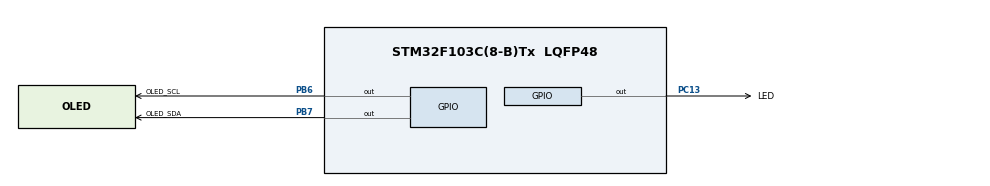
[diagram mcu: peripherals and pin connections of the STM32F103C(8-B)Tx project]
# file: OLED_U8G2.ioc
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Mcu.Family=STM32F1
Mcu.Name=STM32F103C(8-B)Tx
Mcu.Package=LQFP48
NVIC.PriorityGroup=NVIC_PRIORITYGROUP_4
PA13.Mode=Serial_Wire
PA13.Signal=SYS_JTMS-SWDIO
PA14.Mode=Serial_Wire
PA14.Signal=SYS_JTCK-SWCLK
PB6.GPIO_Label=OLED_SCL
PB6.Signal=GPIO_Output
PB7.GPIO_Label=OLED_SDA
PB7.Signal=GPIO_Output
PC13-TAMPER-RTC.GPIO_Label=LED
PC13-TAMPER-RTC.PinState=GPIO_PIN_SET
PC13-TAMPER-RTC.Signal=GPIO_Output
PD0-OSC_IN.Mode=HSE-External-Oscillator
PD0-OSC_IN.Signal=RCC_OSC_IN
PD1-OSC_OUT.Mode=HSE-External-Oscillator
PD1-OSC_OUT.Signal=RCC_OSC_OUT
ProjectManager.HeapSize=0x200
ProjectManager.StackSize=0x400
ProjectManager.TargetToolchain=MDK-ARM
RCC.AHBFreq_Value=72000000
RCC.APB1CLKDivider=RCC_HCLK_DIV2
RCC.APB1Freq_Value=36000000
RCC.APB1TimFreq_Value=72000000
RCC.APB2Freq_Value=72000000
RCC.APB2TimFreq_Value=72000000
RCC.HCLKFreq_Value=72000000
RCC.PLLMUL=RCC_PLL_MUL9
RCC.PLLSourceVirtual=RCC_PLLSOURCE_HSE
RCC.SYSCLKFreq_VALUE=72000000
RCC.SYSCLKSource=RCC_SYSCLKSOURCE_PLLCLK
RCC.USBFreq_Value=72000000
board=custom

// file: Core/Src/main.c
/**
  ******************************************************************************
  * @file    main.c
  * @brief   任务 2：CubeMX 风格 HAL 框架 + U8g2 + SSD1306 IIC OLED
  *
  * 硬件:
  *   OLED VCC -> 3.3V
  *   OLED GND -> GND
  *   OLED SCL -> PB6
  *   OLED SDA -> PB7
  *
  * 功能:
  *   1. U8g2 demo 例程；
  *   2. 显示学号 632407030627 和姓名 王兴；
  *   3. 上下、左右滑动显示；
  *   4. 动态雷达图案。
  ******************************************************************************
  */

#include "main.h"

/* USER CODE BEGIN Includes */
#include "u8g2_port.h"
#include "u8g2_app.h"
/* USER CODE END Includes */

static void SystemClock_Config(void);
static void MX_GPIO_Init(void);

int main(void)
{
    HAL_Init();
    SystemClock_Config();
    MX_GPIO_Init();

    /* USER CODE BEGIN 2 */
    U8G2_Port_Init();
    U8G2_App_Run();
    /* USER CODE END 2 */

    while (1)
    {
    }
}

/**
  * @brief  系统时钟: HSE 8 MHz -> PLL x9 -> SYSCLK 72 MHz
  */
static void SystemClock_Config(void)
{
    RCC_OscInitTypeDef RCC_OscInitStruct = {0};
    RCC_ClkInitTypeDef RCC_ClkInitStruct = {0};

    RCC_OscInitStruct.OscillatorType      = RCC_OSCILLATORTYPE_HSE;
    RCC_OscInitStruct.HSEState            = RCC_HSE_ON;
    RCC_OscInitStruct.HSEPredivValue      = RCC_HSE_PREDIV_DIV1;
    RCC_OscInitStruct.HSIState            = RCC_HSI_ON;
    RCC_OscInitStruct.PLL.PLLState        = RCC_PLL_ON;
    RCC_OscInitStruct.PLL.PLLSource       = RCC_PLLSOURCE_HSE;
    RCC_OscInitStruct.PLL.PLLMUL          = RCC_PLL_MUL9;

    if (HAL_RCC_OscConfig(&RCC_OscInitStruct) != HAL_OK)
    {
        Error_Handler();
    }

    RCC_ClkInitStruct.ClockType      = RCC_CLOCKTYPE_HCLK | RCC_CLOCKTYPE_SYSCLK |
                                       RCC_CLOCKTYPE_PCLK1 | RCC_CLOCKTYPE_PCLK2;
    RCC_ClkInitStruct.SYSCLKSource   = RCC_SYSCLKSOURCE_PLLCLK;
    RCC_ClkInitStruct.AHBCLKDivider  = RCC_SYSCLK_DIV1;
    RCC_ClkInitStruct.APB1CLKDivider = RCC_HCLK_DIV2;
    RCC_ClkInitStruct.APB2CLKDivider = RCC_HCLK_DIV1;

    if (HAL_RCC_ClockConfig(&RCC_ClkInitStruct, FLASH_LATENCY_2) != HAL_OK)
    {
        Error_Handler();
    }
}

static void MX_GPIO_Init(void)
{
    GPIO_InitTypeDef GPIO_InitStruct = {0};

    __HAL_RCC_GPIOC_CLK_ENABLE();

    HAL_GPIO_WritePin(LED_GPIO_Port, LED_Pin, GPIO_PIN_SET);

    GPIO_InitStruct.Pin   = LED_Pin;
    GPIO_InitStruct.Mode  = GPIO_MODE_OUTPUT_PP;
    GPIO_InitStruct.Pull  = GPIO_NOPULL;
    GPIO_InitStruct.Speed = GPIO_SPEED_FREQ_LOW;
    HAL_GPIO_Init(LED_GPIO_Port, &GPIO_InitStruct);
}

void Error_Handler(void)
{
    __disable_irq();
    while (1)
    {
    }
}
